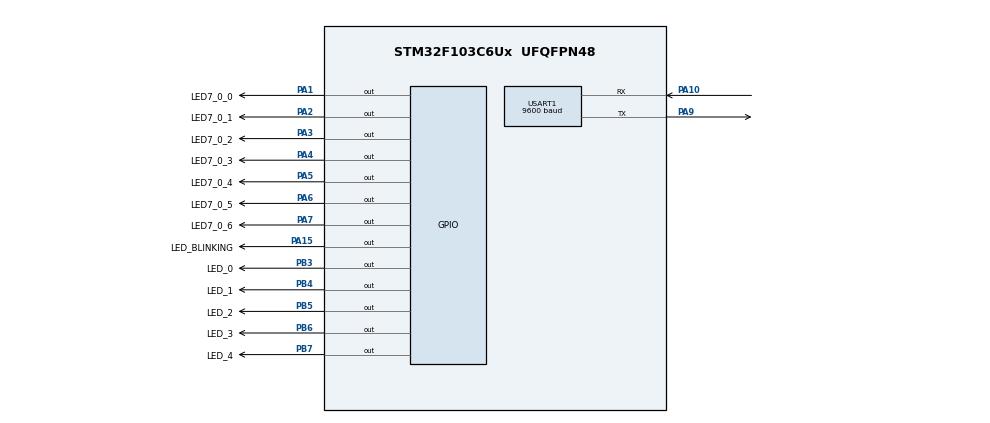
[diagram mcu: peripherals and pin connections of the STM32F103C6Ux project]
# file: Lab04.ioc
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Mcu.Family=STM32F1
Mcu.Name=STM32F103C6Ux
Mcu.Package=UFQFPN48
NVIC.PriorityGroup=NVIC_PRIORITYGROUP_4
NVIC.TIM2_IRQn=true\:0\:0\:false\:false\:true\:true\:true
NVIC.USART1_IRQn=true\:0\:0\:false\:false\:true\:true\:true
PA1.GPIO_Label=LED7_0_0
PA1.Signal=GPIO_Output
PA10.Mode=Asynchronous
PA10.Signal=USART1_RX
PA15.GPIO_Label=LED_BLINKING
PA15.Signal=GPIO_Output
PA2.GPIO_Label=LED7_0_1
PA2.Signal=GPIO_Output
PA3.GPIO_Label=LED7_0_2
PA3.Signal=GPIO_Output
PA4.GPIO_Label=LED7_0_3
PA4.Signal=GPIO_Output
PA5.GPIO_Label=LED7_0_4
PA5.Signal=GPIO_Output
PA6.GPIO_Label=LED7_0_5
PA6.Signal=GPIO_Output
PA7.GPIO_Label=LED7_0_6
PA7.Signal=GPIO_Output
PA9.Mode=Asynchronous
PA9.Signal=USART1_TX
PB3.GPIO_Label=LED_0
PB3.Signal=GPIO_Output
PB4.GPIO_Label=LED_1
PB4.Signal=GPIO_Output
PB5.GPIO_Label=LED_2
PB5.Signal=GPIO_Output
PB6.GPIO_Label=LED_3
PB6.Signal=GPIO_Output
PB7.GPIO_Label=LED_4
PB7.Signal=GPIO_Output
ProjectManager.HeapSize=0x200
ProjectManager.StackSize=0x400
ProjectManager.TargetToolchain=STM32CubeIDE
RCC.APB1Freq_Value=8000000
RCC.APB2Freq_Value=8000000
TIM2.Period=9
TIM2.Prescaler=7999
USART1.BaudRate=9600
USART1.VirtualMode=VM_ASYNC
VP_SYS_VS_ND.Mode=No_Debug
VP_TIM2_VS_ClockSourceINT.Mode=Internal
board=custom

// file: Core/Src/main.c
/* USER CODE BEGIN Header */
/**
  ******************************************************************************
  * @file           : main.c
  * @brief          : Main program body
  ******************************************************************************
  * @attention
  *
  * <h2><center>&copy; Copyright (c) 2022 STMicroelectronics.
  * All rights reserved.</center></h2>
  *
  * This software component is licensed by ST under BSD 3-Clause license,
  * the "License"; You may not use this file except in compliance with the
  * License. You may obtain a copy of the License at:
  *                        opensource.org/licenses/BSD-3-Clause
  *
  ******************************************************************************
  */
/* USER CODE END Header */
#include "main.h"

/* USER CODE BEGIN Includes */
#include "led_processing.h"
#include "scheduler.h"
/* USER CODE END Includes */

TIM_HandleTypeDef htim2;

UART_HandleTypeDef huart1;

void SystemClock_Config(void);
static void MX_GPIO_Init(void);
static void MX_TIM2_Init(void);
static void MX_USART1_UART_Init(void);

/* USER CODE BEGIN 0 */
void led1test(){
	HAL_GPIO_TogglePin(GPIOA, LED_BLINKING_Pin);
}
/* USER CODE END 0 */

int main(void)
{

  /* MCU Configuration--------------------------------------------------------*/

  /* Reset of all peripherals, Initializes the Flash interface and the Systick. */
  HAL_Init();

  /* Configure the system clock */
  SystemClock_Config();

  /* Initialize all configured peripherals */
  MX_GPIO_Init();
  MX_TIM2_Init();
  MX_USART1_UART_Init();
  /* USER CODE BEGIN 2 */
  HAL_TIM_Base_Start_IT(&htim2);
  /* USER CODE END 2 */
  SCH_Init();
  Leds_Init();
  SCH_Add_Task (increase7SegLED, 0, 1000);
  SCH_Add_Task (toggleLED1, 1000, 500);
  SCH_Add_Task (toggleLED2, 3000, 1000);
  SCH_Add_Task (toggleLED3, 2000, 1500);
  SCH_Add_Task (toggleLED4, 2000, 2000);
  SCH_Add_Task (toggleLED5, 4000, 2500);
  /* Infinite loop */
  while (1)
  {
	  SCH_Dispatch_Tasks(&huart1);
  }
}

void SystemClock_Config(void)
{
  RCC_OscInitTypeDef RCC_OscInitStruct = {0};
  RCC_ClkInitTypeDef RCC_ClkInitStruct = {0};

  /** Initializes the RCC Oscillators according to the specified parameters
  * in the RCC_OscInitTypeDef structure.
  */
  RCC_OscInitStruct.OscillatorType = RCC_OSCILLATORTYPE_HSI;
  RCC_OscInitStruct.HSIState = RCC_HSI_ON;
  RCC_OscInitStruct.HSICalibrationValue = RCC_HSICALIBRATION_DEFAULT;
  RCC_OscInitStruct.PLL.PLLState = RCC_PLL_NONE;
  if (HAL_RCC_OscConfig(&RCC_OscInitStruct) != HAL_OK)
  {
    Error_Handler();
  }
  /** Initializes the CPU, AHB and APB buses clocks
  */
  RCC_ClkInitStruct.ClockType = RCC_CLOCKTYPE_HCLK|RCC_CLOCKTYPE_SYSCLK
                              |RCC_CLOCKTYPE_PCLK1|RCC_CLOCKTYPE_PCLK2;
  RCC_ClkInitStruct.SYSCLKSource = RCC_SYSCLKSOURCE_HSI;
  RCC_ClkInitStruct.AHBCLKDivider = RCC_SYSCLK_DIV1;
  RCC_ClkInitStruct.APB1CLKDivider = RCC_HCLK_DIV1;
  RCC_ClkInitStruct.APB2CLKDivider = RCC_HCLK_DIV1;

  if (HAL_RCC_ClockConfig(&RCC_ClkInitStruct, FLASH_LATENCY_0) != HAL_OK)
  {
    Error_Handler();
  }
}

static void MX_TIM2_Init(void)
{

  TIM_ClockConfigTypeDef sClockSourceConfig = {0};
  TIM_MasterConfigTypeDef sMasterConfig = {0};

  htim2.Instance = TIM2;
  htim2.Init.Prescaler = 7999;
  htim2.Init.CounterMode = TIM_COUNTERMODE_UP;
  htim2.Init.Period = 9;
  htim2.Init.ClockDivision = TIM_CLOCKDIVISION_DIV1;
  htim2.Init.AutoReloadPreload = TIM_AUTORELOAD_PRELOAD_DISABLE;
  if (HAL_TIM_Base_Init(&htim2) != HAL_OK)
  {
    Error_Handler();
  }
  sClockSourceConfig.ClockSource = TIM_CLOCKSOURCE_INTERNAL;
  if (HAL_TIM_ConfigClockSource(&htim2, &sClockSourceConfig) != HAL_OK)
  {
    Error_Handler();
  }
  sMasterConfig.MasterOutputTrigger = TIM_TRGO_RESET;
  sMasterConfig.MasterSlaveMode = TIM_MASTERSLAVEMODE_DISABLE;
  if (HAL_TIMEx_MasterConfigSynchronization(&htim2, &sMasterConfig) != HAL_OK)
  {
    Error_Handler();
  }

}

static void MX_USART1_UART_Init(void)
{

  huart1.Instance = USART1;
  huart1.Init.BaudRate = 9600;
  huart1.Init.WordLength = UART_WORDLENGTH_8B;
  huart1.Init.StopBits = UART_STOPBITS_1;
  huart1.Init.Parity = UART_PARITY_NONE;
  huart1.Init.Mode = UART_MODE_TX_RX;
  huart1.Init.HwFlowCtl = UART_HWCONTROL_NONE;
  huart1.Init.OverSampling = UART_OVERSAMPLING_16;
  if (HAL_UART_Init(&huart1) != HAL_OK)
  {
    Error_Handler();
  }

}

static void MX_GPIO_Init(void)
{
  GPIO_InitTypeDef GPIO_InitStruct = {0};

  /* GPIO Ports Clock Enable */
  __HAL_RCC_GPIOA_CLK_ENABLE();
  __HAL_RCC_GPIOB_CLK_ENABLE();

  /*Configure GPIO pin Output Level */
  HAL_GPIO_WritePin(GPIOA, LED7_0_0_Pin|LED7_0_1_Pin|LED7_0_2_Pin|LED7_0_3_Pin
                          |LED7_0_4_Pin|LED7_0_5_Pin|LED7_0_6_Pin|LED_BLINKING_Pin, GPIO_PIN_RESET);

  /*Configure GPIO pin Output Level */
  HAL_GPIO_WritePin(GPIOB, LED_0_Pin|LED_1_Pin|LED_2_Pin|LED_3_Pin
                          |LED_4_Pin, GPIO_PIN_RESET);

  /*Configure GPIO pins : LED7_0_0_Pin LED7_0_1_Pin LED7_0_2_Pin LED7_0_3_Pin
                           LED7_0_4_Pin LED7_0_5_Pin LED7_0_6_Pin LED_BLINKING_Pin */
  GPIO_InitStruct.Pin = LED7_0_0_Pin|LED7_0_1_Pin|LED7_0_2_Pin|LED7_0_3_Pin
                          |LED7_0_4_Pin|LED7_0_5_Pin|LED7_0_6_Pin|LED_BLINKING_Pin;
  GPIO_InitStruct.Mode = GPIO_MODE_OUTPUT_PP;
  GPIO_InitStruct.Pull = GPIO_NOPULL;
  GPIO_InitStruct.Speed = GPIO_SPEED_FREQ_LOW;
  HAL_GPIO_Init(GPIOA, &GPIO_InitStruct);

  /*Configure GPIO pins : LED_0_Pin LED_1_Pin LED_2_Pin LED_3_Pin
                           LED_4_Pin */
  GPIO_InitStruct.Pin = LED_0_Pin|LED_1_Pin|LED_2_Pin|LED_3_Pin
                          |LED_4_Pin;
  GPIO_InitStruct.Mode = GPIO_MODE_OUTPUT_PP;
  GPIO_InitStruct.Pull = GPIO_NOPULL;
  GPIO_InitStruct.Speed = GPIO_SPEED_FREQ_LOW;
  HAL_GPIO_Init(GPIOB, &GPIO_InitStruct);

}

/* USER CODE BEGIN 4 */
int counter = 100;
void HAL_TIM_PeriodElapsedCallback ( TIM_HandleTypeDef * htim )
{
	if ( counter == 100 ) HAL_GPIO_TogglePin (GPIOA , LED_BLINKING_Pin);
	counter--;
	if( counter <= 0 ) counter = 100;

	SCH_Update();
}
/* USER CODE END 4 */

void Error_Handler(void)
{
  __disable_irq();
  while (1)
  {
  }
}

/************************ (C) COPYRIGHT STMicroelectronics *****END OF FILE****/
